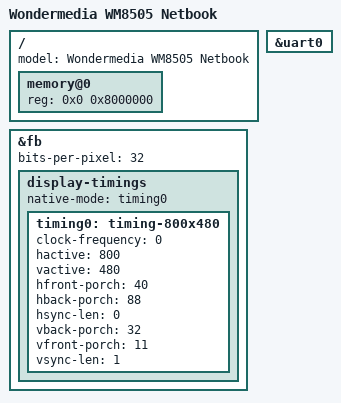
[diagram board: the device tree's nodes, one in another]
// SPDX-License-Identifier: GPL-2.0-or-later
/*
 * wm8505-ref.dts - Device tree file for Wondermedia WM8505 reference netbook
 *
 * Copyright (C) 2012 Tony Prisk <linux@prisktech.co.nz>
 */

/dts-v1/;
/include/ "wm8505.dtsi"

/ {
	model = "Wondermedia WM8505 Netbook";

	memory@0 {
		device_type = "memory";
		reg = <0x0 0x8000000>;
	};
};

&fb {
	bits-per-pixel = <32>;
	display-timings {
		native-mode = <&timing0>;
		timing0: timing-800x480 {
			clock-frequency = <0>; /* unused but required */
			hactive = <800>;
			vactive = <480>;
			hfront-porch = <40>;
			hback-porch = <88>;
			hsync-len = <0>;
			vback-porch = <32>;
			vfront-porch = <11>;
			vsync-len = <1>;
		};
	};
};

&uart0 {
	status = "okay";
};
